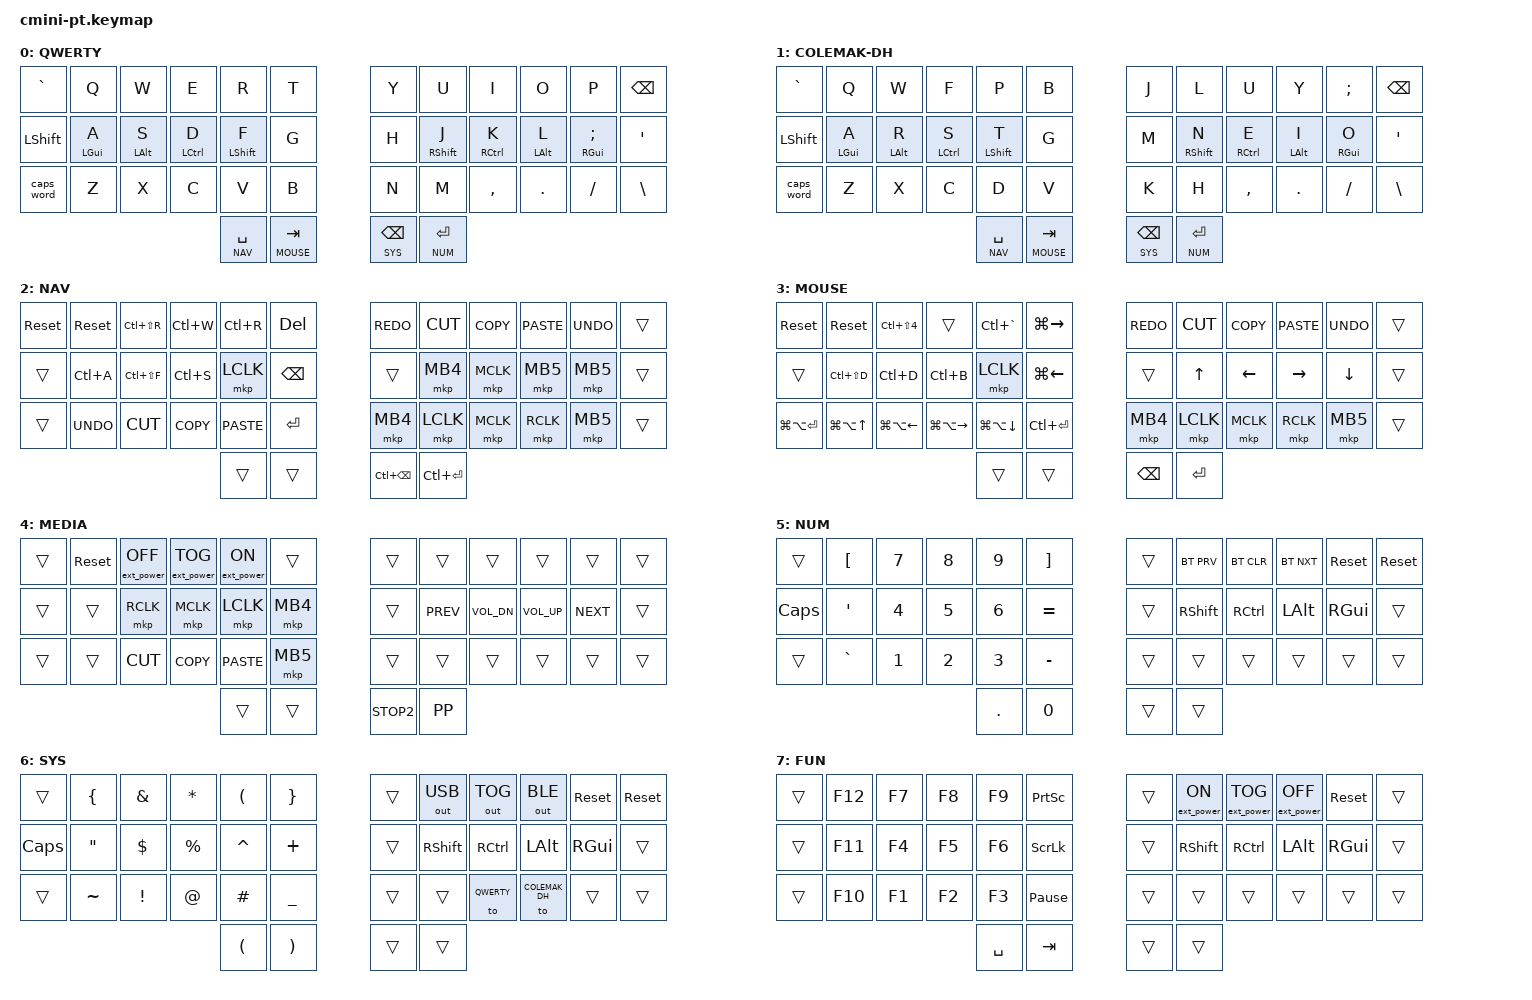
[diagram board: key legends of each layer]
#include <behaviors.dtsi>
#include <dt-bindings/zmk/keys.h>
#include <dt-bindings/zmk/bt.h>
#include <dt-bindings/zmk/outputs.h>
#include <dt-bindings/zmk/ext_power.h>
#include <dt-bindings/zmk/mouse.h>
#define QWERTY 0
#define COLEMAK_DH 1
#define NAV 2
#define MOUSE 3
#define MEDIA 4
#define NUM 5
#define SYS 6
#define FUN 7


#define UNDO LC(Z)
#define REDO LC(Y)
#define COPY LC(C)
#define CUT LC(X)
#define PASTE LC(V)

#define P_ESC 0 42
#define P_Q 1 43
#define P_W 2 44
#define P_E 3 45
#define P_R 4 46
#define P_T 5 47
#define P_Y 6 48
#define P_U 7 49
#define P_I 8 50
#define P_O 9 51
#define P_P 10 52
#define P_BSPC 11 53
#define P_TAB 12 54
#define P_A 13 55
#define P_S 14 56
#define P_D 15 57
#define P_F 16 58
#define P_G 17 59
#define P_H 18 60
#define P_J 19 61
#define P_K 20 62
#define P_L 21 63
#define P_SEMI 22 64
#define P_SQT 23 65
#define P_CAPS 24 66
#define P_Z 25 67
#define P_X 26 68
#define P_C 27 69
#define P_V 28 70
#define P_B 29 71
#define P_N 30 72
#define P_M 31 73
#define P_COMMA 32 74
#define P_DOT 33 75
#define P_FSLH 34 76
#define P_BSLH 35 77

#define P_NAV 36 78
#define P_MOUSE 37 79
#define P_RIGHT 38
#define P_SYS 41 81
#define P_NUM 40 80
#define P_LEFT 39

#define KEYS_L P_ESC P_Q P_W P_E P_R P_T P_TAB P_A P_S P_D P_F P_G P_CAPS P_Z P_X P_C P_V P_B 
#define KEYS_R P_Y P_U P_I P_O P_P P_BSPC P_H P_J P_K P_L P_SEMI P_SQT P_N P_M P_COMMA P_DOT P_FSLH P_BSLH 
#define THUMBS P_NAV P_MOUSE P_RIGHT P_SYS P_NUM P_LEFT

#define COMBO_TIMEOUT 200
#define MACRO_TAP 10
#define MACRO_WAIT 0
&sk {
    release-after-ms = <2000>;
    quick-release;
};

&caps_word {
    continue-list = <UNDERSCORE MINUS>;
};

&lt { 
    flavor = "hold-preferred";
    tapping-term-ms = <125>;
    quick-tap-ms = <200>; 
};

/{
  trackball_peripheral_listener {
        compatible = "zmk,input-behavior-listener";
        device = <&trackball>;
        layers = <0 1 2 3 4 5 6 7>;
        evt-type = <INPUT_EV_REL>;
        x-input-code = <INPUT_REL_MISC>;
        y-input-code = <INPUT_REL_Y>;
   };

  trackpad_peripheral_scroll_listener {
        compatible = "zmk,input-behavior-listener";
        device = <&trackpad>;
        layers = <0 1 2 3 4 5 6 7>;
        evt-type = <INPUT_EV_REL>;
        x-input-code = <INPUT_REL_MISC>;
        y-input-code = <INPUT_REL_HWHEEL>;
   };
};



/ {

    behaviors {
        lh_hmsf: left_hand_homerow_mods_shift {
            compatible = "zmk,behavior-hold-tap";
            label = "LEFT_HOMEROW_MODS_SHIFT";
            #binding-cells = <2>;
            flavor = "tap-unless-interrupted";
            tapping-term-ms = <150>;                       
            quick-tap-ms = <125>;
            global-quick-tap;     
            bindings = <&kp>, <&kp>;
            hold-trigger-key-positions = <KEYS_R THUMBS>;
            //hold-trigger-on-release;             // delay positional check until key-release
        };

        rh_hmsf: right_hand_homerow_mods_shift {
            compatible = "zmk,behavior-hold-tap";
            label = "RIGHT_HOMEROW_MODS_SHIFT";
            #binding-cells = <2>;
            flavor = "tap-unless-interrupted";
            tapping-term-ms = <150>;                       
            quick-tap-ms = <125>;
            global-quick-tap;       
            bindings = <&kp>, <&kp>;
            hold-trigger-key-positions = <KEYS_L THUMBS>;
            //hold-trigger-on-release;             // delay positional check until key-release
        };

        lh_hmctrl: left_hand_homerow_mods_control {
            compatible = "zmk,behavior-hold-tap";
            label = "LEFT_HOMEROW_MODS_CONTROL";
            #binding-cells = <2>;
            tapping-term-ms = <170>;
            quick-tap-ms = <125>;
            global-quick-tap;
            flavor = "tap-preferred";    
            bindings = <&kp>, <&kp>;
            hold-trigger-key-positions = <KEYS_R THUMBS>;
            //hold-trigger-on-release;             // delay positional check until key-release
        };

        rh_hmctrl: right_hand_homerow_mods_control {
            compatible = "zmk,behavior-hold-tap";
            label = "RIGHT_HOMEROW_MODS_CONTROL";
            #binding-cells = <2>;
            tapping-term-ms = <170>;
            quick-tap-ms = <125>;
            global-quick-tap;
            flavor = "tap-preferred";       
            bindings = <&kp>, <&kp>;
            hold-trigger-key-positions = <KEYS_L THUMBS>;
            //hold-trigger-on-release;             // delay positional check until key-release
        };

        lh_hmgui: left_hand_homerow_mods_gui {
            compatible = "zmk,behavior-hold-tap";
            label = "LEFT_HOMEROW_MODS_GUI";
            #binding-cells = <2>;
            tapping-term-ms = <220>;
            quick-tap-ms = <125>;
            global-quick-tap;
            flavor = "tap-preferred";
            bindings = <&kp>, <&kp>;
            hold-trigger-key-positions = <KEYS_R THUMBS>;
            //hold-trigger-on-release;             // delay positional check until key-release
        };

        rh_hmgui: right_hand_homerow_mods_gui {
            compatible = "zmk,behavior-hold-tap";
            label = "RIGHT_HOMEROW_MODS_GUI";
            #binding-cells = <2>;
            tapping-term-ms = <220>;
            quick-tap-ms = <125>;
            global-quick-tap;
            flavor = "tap-preferred";
            bindings = <&kp>, <&kp>;
            hold-trigger-key-positions = <KEYS_L THUMBS>;
            //hold-trigger-on-release;             // delay positional check until key-release
        };
    };


    keymap {
        compatible = "zmk,keymap";

        qwerty {
            label = "QWERTY";
            bindings = <
                &kp GRAVE   &kp Q  &kp W  &kp E  &kp R  &kp T               &kp Y  &kp U  &kp I     &kp O   &kp P    &kp BSPC
                &kp LSHIFT &lh_hmgui LGUI A  &lh_hmgui LALT S  &lh_hmctrl LCTRL D  &lh_hmsf LSHIFT F  &kp G               &kp H  &rh_hmsf RSHIFT J  &rh_hmctrl RCTRL K     &rh_hmgui LALT L   &rh_hmgui RGUI SEMI &kp SQT
                &caps_word &kp Z  &kp X  &kp C  &kp V  &kp B               &kp N  &kp M  &kp COMMA &kp DOT &kp FSLH &kp BSLH
                        &lt NAV SPACE  &lt MOUSE TAB                       &lt SYS BSPC  &lt NUM ENTER
            >;
        };

        colemak-dh {
            label = "COLEMAK-DH";
            bindings = <
                &kp GRAVE   &kp Q  &kp W  &kp F  &kp P  &kp B               &kp J  &kp L  &kp U     &kp Y   &kp SEMI    &kp BSPC
                &kp LSHIFT &lh_hmgui LGUI A  &lh_hmgui LALT R  &lh_hmctrl LCTRL S  &lh_hmsf LSHIFT T  &kp G               &kp M  &rh_hmsf RSHIFT N  &rh_hmctrl RCTRL E     &rh_hmgui LALT I   &rh_hmgui RGUI O &kp SQT
                &caps_word &kp Z  &kp X  &kp C  &kp D  &kp V               &kp K  &kp H  &kp COMMA &kp DOT &kp FSLH &kp BSLH
                        &lt NAV SPACE  &lt MOUSE TAB                       &lt SYS BSPC  &lt NUM ENTER
            >;
        };

        nav {
            label = "NAV";
            bindings = <
                &sys_reset  &sys_reset &kp LC(LS(R)) &kp LC(W) &kp LC(R) &kp DEL                &kp REDO&kp CUT &kp COPY &kp PASTE &kp UNDO &trans
                &trans  &kp LC(A) &kp LC(LS(F)) &kp LC(S) &mkp LCLK &kp BSPC      &trans &mkp MB4 &mkp MCLK &mkp MB5 &mkp MB5 &trans
                &trans  &kp UNDO &kp CUT &kp COPY &kp PASTE &kp ENTER      &mkp MB4 &mkp LCLK &mkp MCLK &mkp RCLK &mkp MB5 &trans
                                             &trans  &trans                &kp LC(BSPC) &kp LC(ENTER)
            >;
        };

        mouse {
            label = "MOUSE";
            bindings = <
                &sys_reset  &sys_reset &kp LC(LS(N4)) &trans &kp LC(GRAVE) &kp LG(RIGHT)                &kp REDO &kp CUT &kp COPY &kp PASTE &kp UNDO &trans
                &trans  &kp LC(LS(D)) &kp LC(D) &kp LC(B) &mkp LCLK &kp LG(LEFT)      &trans &kp UP &kp LEFT &kp RIGHT &kp DOWN &trans
                &kp LG(LA(ENTER))  &kp LG(LA(UP)) &kp LG(LA(LEFT)) &kp LG(LA(RIGHT)) &kp LG(LA(DOWN)) &kp LC(ENTER)         &mkp MB4 &mkp LCLK &mkp MCLK &mkp RCLK &mkp MB5 &trans
                                              &trans  &trans                     &kp BSPC &kp ENTER
            >;
        };


        media {
            label = "MEDIA";
            bindings = <
                &trans  &sys_reset &ext_power EP_OFF &ext_power EP_TOG &ext_power EP_ON &trans                &trans  &trans &trans &trans &trans &trans
                &trans  &trans &mkp RCLK &mkp MCLK &mkp LCLK &mkp MB4      &trans  &kp K_PREV &kp K_VOL_DN &kp K_VOL_UP &kp K_NEXT &trans
                &trans  &trans &kp CUT &kp COPY &kp PASTE &mkp MB5                &trans  &trans &trans &trans &trans &trans
                                             &trans  &trans               &kp K_STOP2 &kp K_PP
            >;
        };

        num {
            label = "NUM";
            bindings = <
                &trans  &kp LBKT &kp N7 &kp N8 &kp N9 &kp RBKT             &trans  &bt BT_PRV &bt BT_CLR &bt BT_NXT &sys_reset &sys_reset
                &kp CAPS  &kp SQT &kp N4 &kp N5 &kp N6 &kp EQUAL          &trans  &kp RSHFT &kp RCTRL &kp LALT &kp RGUI &trans
                &trans  &kp GRAVE &kp N1 &kp N2 &kp N3 &kp MINUS           &trans  &trans &trans &trans &trans &trans
                                             &kp DOT &kp N0                &trans &trans
            >;
        };

        sys {
            label = "SYS";
            bindings = <
                &trans  &kp LBRC &kp AMPERSAND &kp ASTERISK &kp LPAR &kp RBRC             &trans  &out OUT_USB &out OUT_TOG &out OUT_BLE &sys_reset &sys_reset
                &kp CAPS  &kp DQT &kp DOLLAR &kp PERCENT &kp CARET &kp PLUS          &trans  &kp RSHFT &kp RCTRL &kp LALT &kp RGUI &trans
                &trans  &kp TILDE &kp EXCL &kp AT &kp HASH &kp UNDER           &trans  &trans &to QWERTY &to COLEMAK_DH &trans &trans
                                             &kp LPAR &kp RPAR                 &trans &trans
            >;
        };

        fun {
            label = "FUN";
            bindings = <
                &trans  &kp F12 &kp F7 &kp F8 &kp F9 &kp PSCRN              &trans  &ext_power EP_ON &ext_power EP_TOG &ext_power EP_OFF &sys_reset &trans
                &trans  &kp F11 &kp F4 &kp F5 &kp F6 &kp SLCK               &trans  &kp RSHFT &kp RCTRL &kp LALT &kp RGUI &trans
                &trans  &kp F10 &kp F1 &kp F2 &kp F3 &kp PAUSE_BREAK        &trans  &trans &trans &trans &trans &trans
                                             &kp SPACE &kp TAB              &trans &trans
            >; 
        };

    };
};
 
